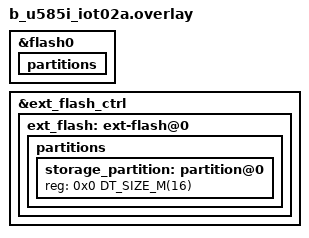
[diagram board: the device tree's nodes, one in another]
/**
 * @copyright Copyright (c) contributors to Project Ocre,
 * which has been established as Project Ocre a Series of LF Projects, LLC
 *
 * SPDX-License-Identifier: Apache-2.0
 */
 
/* The storage partition will be in the external flash */
&flash0 {
    partitions {
       /delete-node/ partition@f0000;
    };
};

&ext_flash_ctrl {
    ext_flash: ext-flash@0 {
        partitions {
            /* Use the first partition from flash. */
            storage_partition: partition@0 {
                reg = <0x0 DT_SIZE_M(16)>;
            };
        };
    };
};
